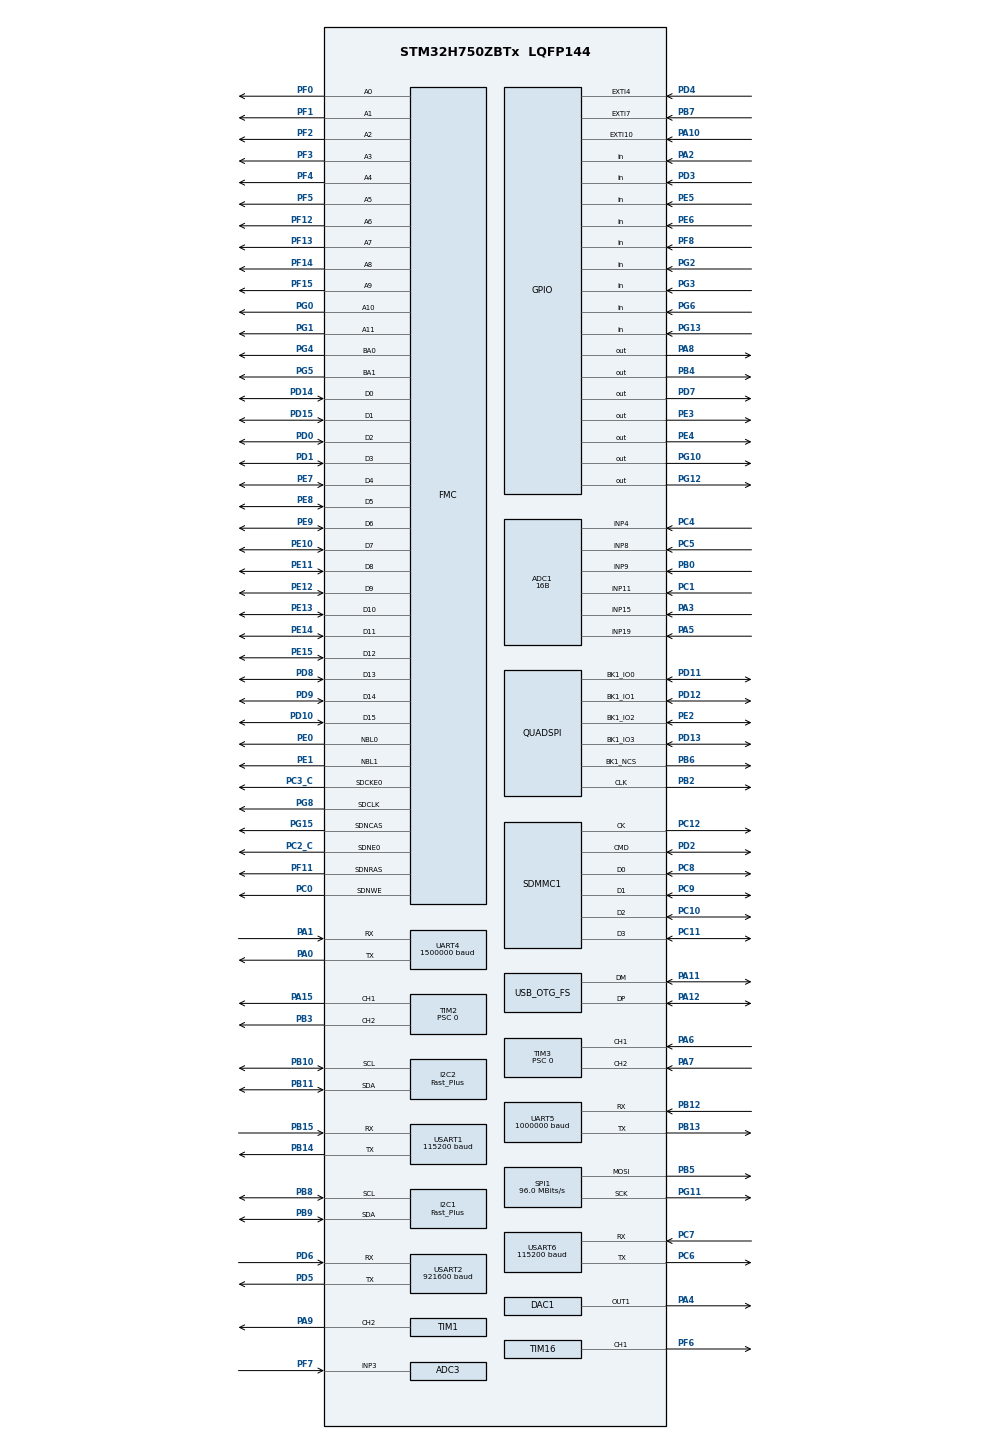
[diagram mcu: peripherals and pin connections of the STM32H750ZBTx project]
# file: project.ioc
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ADC1.Channel-12\#ChannelRegularConversion=ADC_CHANNEL_9
ADC1.Channel-14\#ChannelRegularConversion=ADC_CHANNEL_11
ADC1.Channel-15\#ChannelRegularConversion=ADC_CHANNEL_15
ADC1.Channel-16\#ChannelRegularConversion=ADC_CHANNEL_19
ADC1.Channel-17\#ChannelRegularConversion=ADC_CHANNEL_8
ADC1.Channel-18\#ChannelRegularConversion=ADC_CHANNEL_4
ADC1.ClockPrescaler=ADC_CLOCK_ASYNC_DIV1
ADC1.ClockPrescalerADC3=ADC_CLOCK_ASYNC_DIV1
ADC1.ContinuousConvMode=ENABLE
ADC1.ConversionDataManagement=ADC_CONVERSIONDATA_DMA_CIRCULAR
ADC1.DiscontinuousConvMode=DISABLE
ADC1.EOCSelection=ADC_EOC_SEQ_CONV
ADC1.EnableInjectedConversion=DISABLE
ADC1.EnableRegularConversion=ENABLE
ADC1.NbrOfConversion=6
ADC1.NbrOfConversionFlag=1
ADC1.OffsetNumber-12\#ChannelRegularConversion=ADC_OFFSET_NONE
ADC1.OffsetNumber-14\#ChannelRegularConversion=ADC_OFFSET_NONE
ADC1.OffsetNumber-15\#ChannelRegularConversion=ADC_OFFSET_NONE
ADC1.OffsetNumber-16\#ChannelRegularConversion=ADC_OFFSET_NONE
ADC1.OffsetNumber-17\#ChannelRegularConversion=ADC_OFFSET_NONE
ADC1.OffsetNumber-18\#ChannelRegularConversion=ADC_OFFSET_NONE
ADC1.OffsetSignedSaturation-12\#ChannelRegularConversion=DISABLE
ADC1.OffsetSignedSaturation-14\#ChannelRegularConversion=DISABLE
ADC1.OffsetSignedSaturation-15\#ChannelRegularConversion=DISABLE
ADC1.OffsetSignedSaturation-16\#ChannelRegularConversion=DISABLE
ADC1.OffsetSignedSaturation-17\#ChannelRegularConversion=DISABLE
ADC1.OffsetSignedSaturation-18\#ChannelRegularConversion=DISABLE
ADC1.Overrun=ADC_OVR_DATA_OVERWRITTEN
ADC1.OversamplingMode=DISABLE
ADC1.Rank-12\#ChannelRegularConversion=1
ADC1.Rank-14\#ChannelRegularConversion=2
ADC1.Rank-15\#ChannelRegularConversion=3
ADC1.Rank-16\#ChannelRegularConversion=4
ADC1.Rank-17\#ChannelRegularConversion=5
ADC1.Rank-18\#ChannelRegularConversion=6
ADC1.Resolution=ADC_RESOLUTION_16B
ADC1.SamplingTime-12\#ChannelRegularConversion=ADC_SAMPLETIME_810CYCLES_5
ADC1.SamplingTime-14\#ChannelRegularConversion=ADC_SAMPLETIME_810CYCLES_5
ADC1.SamplingTime-15\#ChannelRegularConversion=ADC_SAMPLETIME_810CYCLES_5
ADC1.SamplingTime-16\#ChannelRegularConversion=ADC_SAMPLETIME_810CYCLES_5
ADC1.SamplingTime-17\#ChannelRegularConversion=ADC_SAMPLETIME_810CYCLES_5
ADC1.SamplingTime-18\#ChannelRegularConversion=ADC_SAMPLETIME_810CYCLES_5
ADC1.master=1
ADC3.Channel-1\#ChannelRegularConversion=ADC_CHANNEL_3
ADC3.ClockPrescaler=ADC_CLOCK_ASYNC_DIV1
ADC3.ClockPrescalerADC3=ADC_CLOCK_ASYNC_DIV1
ADC3.ContinuousConvMode=ENABLE
ADC3.ConversionDataManagement=ADC_CONVERSIONDATA_DMA_CIRCULAR
ADC3.EOCSelection=ADC_EOC_SEQ_CONV
ADC3.NbrOfConversionFlag=1
ADC3.OffsetNumber-1\#ChannelRegularConversion=ADC_OFFSET_NONE
ADC3.OffsetSignedSaturation-1\#ChannelRegularConversion=DISABLE
ADC3.Overrun=ADC_OVR_DATA_OVERWRITTEN
ADC3.Rank-1\#ChannelRegularConversion=1
ADC3.SamplingTime-1\#ChannelRegularConversion=ADC_SAMPLETIME_810CYCLES_5
CORTEX_M7.AccessPermission-Cortex_Memory_Protection_Unit_Region0_Settings=MPU_REGION_FULL_ACCESS
CORTEX_M7.AccessPermission-Cortex_Memory_Protection_Unit_Region1_Settings=MPU_REGION_FULL_ACCESS
CORTEX_M7.AccessPermission-Cortex_Memory_Protection_Unit_Region2_Settings=MPU_REGION_FULL_ACCESS
CORTEX_M7.AccessPermission_Spec=MPU_REGION_FULL_ACCESS
CORTEX_M7.BaseAddress-Cortex_Memory_Protection_Unit_Region0_Settings=0x24000000
CORTEX_M7.BaseAddress-Cortex_Memory_Protection_Unit_Region1_Settings=0x30000000
CORTEX_M7.BaseAddress-Cortex_Memory_Protection_Unit_Region2_Settings=0x30020000
CORTEX_M7.BaseAddress_Spec=0x24000000
CORTEX_M7.CPU_DCache=Enabled
CORTEX_M7.CPU_ICache=Enabled
CORTEX_M7.DisableExec_Spec=MPU_INSTRUCTION_ACCESS_ENABLE
CORTEX_M7.Enable-Cortex_Memory_Protection_Unit_Region0_Settings=MPU_REGION_ENABLE
CORTEX_M7.Enable-Cortex_Memory_Protection_Unit_Region1_Settings=MPU_REGION_ENABLE
CORTEX_M7.Enable-Cortex_Memory_Protection_Unit_Region2_Settings=MPU_REGION_ENABLE
CORTEX_M7.IsBufferable-Cortex_Memory_Protection_Unit_Region0_Settings=MPU_ACCESS_NOT_BUFFERABLE
CORTEX_M7.IsBufferable-Cortex_Memory_Protection_Unit_Region1_Settings=MPU_ACCESS_NOT_BUFFERABLE
CORTEX_M7.IsBufferable-Cortex_Memory_Protection_Unit_Region2_Settings=MPU_ACCESS_NOT_BUFFERABLE
CORTEX_M7.IsBufferable_Spec=MPU_ACCESS_BUFFERABLE
CORTEX_M7.IsCacheable-Cortex_Memory_Protection_Unit_Region0_Settings=MPU_ACCESS_CACHEABLE
CORTEX_M7.IsCacheable-Cortex_Memory_Protection_Unit_Region1_Settings=MPU_ACCESS_CACHEABLE
CORTEX_M7.IsCacheable-Cortex_Memory_Protection_Unit_Region2_Settings=MPU_ACCESS_CACHEABLE
CORTEX_M7.IsCacheable_Spec=MPU_ACCESS_CACHEABLE
CORTEX_M7.IsShareable_Spec=MPU_ACCESS_NOT_SHAREABLE
CORTEX_M7.MPU_Control=MPU_HFNMI_PRIVDEF
CORTEX_M7.Size-Cortex_Memory_Protection_Unit_Region0_Settings=MPU_REGION_SIZE_512KB
CORTEX_M7.Size-Cortex_Memory_Protection_Unit_Region1_Settings=MPU_REGION_SIZE_128KB
CORTEX_M7.Size-Cortex_Memory_Protection_Unit_Region2_Settings=MPU_REGION_SIZE_128KB
CORTEX_M7.Size_Spec=MPU_REGION_SIZE_512KB
CORTEX_M7.SubRegionDisable_Spec=0
CORTEX_M7.TypeExtField-Cortex_Memory_Protection_Unit_Region0_Settings=MPU_TEX_LEVEL0
CORTEX_M7.TypeExtField-Cortex_Memory_Protection_Unit_Region1_Settings=MPU_TEX_LEVEL0
CORTEX_M7.TypeExtField-Cortex_Memory_Protection_Unit_Region2_Settings=MPU_TEX_LEVEL0
CORTEX_M7.TypeExtField_Spec=MPU_TEX_LEVEL1
CORTEX_M7.default_mode_Activation=0
DAC1.DAC1_OutputBuffer-DAC_OUT1=DAC_OUTPUTBUFFER_DISABLE
DAC1.DAC_Channel-DAC_OUT1=DAC_CHANNEL_1
DAC1.DAC_Trigger-DAC_OUT1=DAC_TRIGGER_T15_TRGO
Dma.ADC1.2.Direction=DMA_PERIPH_TO_MEMORY
Dma.ADC1.2.EventEnable=DISABLE
Dma.ADC1.2.FIFOMode=DMA_FIFOMODE_DISABLE
Dma.ADC1.2.Instance=DMA2_Stream0
Dma.ADC1.2.MemDataAlignment=DMA_MDATAALIGN_HALFWORD
Dma.ADC1.2.MemInc=DMA_MINC_ENABLE
Dma.ADC1.2.Mode=DMA_CIRCULAR
Dma.ADC1.2.PeriphDataAlignment=DMA_PDATAALIGN_HALFWORD
Dma.ADC1.2.PeriphInc=DMA_PINC_DISABLE
Dma.ADC1.2.Polarity=HAL_DMAMUX_REQ_GEN_RISING
Dma.ADC1.2.Priority=DMA_PRIORITY_HIGH
Dma.ADC1.2.RequestNumber=1
Dma.ADC1.2.SignalID=NONE
Dma.ADC1.2.SyncEnable=DISABLE
Dma.ADC1.2.SyncPolarity=HAL_DMAMUX_SYNC_NO_EVENT
Dma.ADC1.2.SyncRequestNumber=1
Dma.ADC1.2.SyncSignalID=NONE
Dma.ADC3.9.Direction=DMA_PERIPH_TO_MEMORY
Dma.ADC3.9.EventEnable=DISABLE
Dma.ADC3.9.FIFOMode=DMA_FIFOMODE_DISABLE
Dma.ADC3.9.Instance=DMA2_Stream6
Dma.ADC3.9.MemDataAlignment=DMA_MDATAALIGN_HALFWORD
Dma.ADC3.9.MemInc=DMA_MINC_ENABLE
Dma.ADC3.9.Mode=DMA_CIRCULAR
Dma.ADC3.9.PeriphDataAlignment=DMA_PDATAALIGN_HALFWORD
Dma.ADC3.9.PeriphInc=DMA_PINC_DISABLE
Dma.ADC3.9.Polarity=HAL_DMAMUX_REQ_GEN_RISING
Dma.ADC3.9.Priority=DMA_PRIORITY_HIGH
Dma.ADC3.9.RequestNumber=1
Dma.ADC3.9.SignalID=NONE
Dma.ADC3.9.SyncEnable=DISABLE
Dma.ADC3.9.SyncPolarity=HAL_DMAMUX_SYNC_NO_EVENT
Dma.ADC3.9.SyncRequestNumber=1
Dma.ADC3.9.SyncSignalID=NONE
Dma.DAC1_CH1.3.Direction=DMA_MEMORY_TO_PERIPH
Dma.DAC1_CH1.3.EventEnable=DISABLE
Dma.DAC1_CH1.3.FIFOMode=DMA_FIFOMODE_DISABLE
Dma.DAC1_CH1.3.Instance=DMA1_Stream1
Dma.DAC1_CH1.3.MemDataAlignment=DMA_MDATAALIGN_HALFWORD
Dma.DAC1_CH1.3.MemInc=DMA_MINC_ENABLE
Dma.DAC1_CH1.3.Mode=DMA_NORMAL
Dma.DAC1_CH1.3.PeriphDataAlignment=DMA_PDATAALIGN_HALFWORD
Dma.DAC1_CH1.3.PeriphInc=DMA_PINC_DISABLE
Dma.DAC1_CH1.3.Polarity=HAL_DMAMUX_REQ_GEN_RISING
Dma.DAC1_CH1.3.Priority=DMA_PRIORITY_LOW
Dma.DAC1_CH1.3.RequestNumber=1
Dma.DAC1_CH1.3.SignalID=NONE
Dma.DAC1_CH1.3.SyncEnable=DISABLE
Dma.DAC1_CH1.3.SyncPolarity=HAL_DMAMUX_SYNC_NO_EVENT
Dma.DAC1_CH1.3.SyncRequestNumber=1
Dma.DAC1_CH1.3.SyncSignalID=NONE
Dma.Request0=UART4_TX
Dma.Request1=TIM16_CH1
Dma.Request10=USART6_RX
Dma.Request11=USART1_RX
Dma.Request12=USART1_TX
Dma.Request13=UART4_RX
Dma.Request14=USART6_TX
Dma.Request2=ADC1
Dma.Request3=DAC1_CH1
Dma.Request4=TIM1_CH2
Dma.Request5=SPI1_TX
Dma.Request6=USART2_RX
Dma.Request7=USART2_TX
Dma.Request8=UART5_TX
Dma.Request9=ADC3
Dma.SPI1_TX.5.Direction=DMA_MEMORY_TO_PERIPH
Dma.SPI1_TX.5.EventEnable=DISABLE
Dma.SPI1_TX.5.FIFOMode=DMA_FIFOMODE_DISABLE
Dma.SPI1_TX.5.Instance=DMA1_Stream6
Dma.SPI1_TX.5.MemDataAlignment=DMA_MDATAALIGN_BYTE
Dma.SPI1_TX.5.MemInc=DMA_MINC_ENABLE
Dma.SPI1_TX.5.Mode=DMA_NORMAL
Dma.SPI1_TX.5.PeriphDataAlignment=DMA_PDATAALIGN_BYTE
Dma.SPI1_TX.5.PeriphInc=DMA_PINC_DISABLE
Dma.SPI1_TX.5.Polarity=HAL_DMAMUX_REQ_GEN_RISING
Dma.SPI1_TX.5.Priority=DMA_PRIORITY_LOW
Dma.SPI1_TX.5.RequestNumber=1
Dma.SPI1_TX.5.SignalID=NONE
Dma.SPI1_TX.5.SyncEnable=DISABLE
Dma.SPI1_TX.5.SyncPolarity=HAL_DMAMUX_SYNC_NO_EVENT
Dma.SPI1_TX.5.SyncRequestNumber=1
Dma.SPI1_TX.5.SyncSignalID=NONE
Dma.TIM16_CH1.1.Direction=DMA_MEMORY_TO_PERIPH
Dma.TIM16_CH1.1.EventEnable=DISABLE
Dma.TIM16_CH1.1.FIFOMode=DMA_FIFOMODE_DISABLE
Dma.TIM16_CH1.1.Instance=DMA1_Stream0
Dma.TIM16_CH1.1.MemDataAlignment=DMA_MDATAALIGN_HALFWORD
Dma.TIM16_CH1.1.MemInc=DMA_MINC_ENABLE
Dma.TIM16_CH1.1.Mode=DMA_CIRCULAR
Dma.TIM16_CH1.1.PeriphDataAlignment=DMA_PDATAALIGN_HALFWORD
Dma.TIM16_CH1.1.PeriphInc=DMA_PINC_DISABLE
Dma.TIM16_CH1.1.Polarity=HAL_DMAMUX_REQ_GEN_RISING
Dma.TIM16_CH1.1.Priority=DMA_PRIORITY_LOW
Dma.TIM16_CH1.1.RequestNumber=1
Dma.TIM16_CH1.1.SignalID=NONE
Dma.TIM16_CH1.1.SyncEnable=DISABLE
Dma.TIM16_CH1.1.SyncPolarity=HAL_DMAMUX_SYNC_NO_EVENT
Dma.TIM16_CH1.1.SyncRequestNumber=1
Dma.TIM16_CH1.1.SyncSignalID=NONE
Dma.TIM1_CH2.4.Direction=DMA_MEMORY_TO_PERIPH
Dma.TIM1_CH2.4.EventEnable=DISABLE
Dma.TIM1_CH2.4.FIFOMode=DMA_FIFOMODE_DISABLE
Dma.TIM1_CH2.4.Instance=DMA1_Stream3
Dma.TIM1_CH2.4.MemDataAlignment=DMA_MDATAALIGN_HALFWORD
Dma.TIM1_CH2.4.MemInc=DMA_MINC_ENABLE
Dma.TIM1_CH2.4.Mode=DMA_NORMAL
Dma.TIM1_CH2.4.PeriphDataAlignment=DMA_PDATAALIGN_HALFWORD
Dma.TIM1_CH2.4.PeriphInc=DMA_PINC_DISABLE
Dma.TIM1_CH2.4.Polarity=HAL_DMAMUX_REQ_GEN_RISING
Dma.TIM1_CH2.4.Priority=DMA_PRIORITY_LOW
Dma.TIM1_CH2.4.RequestNumber=1
Dma.TIM1_CH2.4.SignalID=NONE
Dma.TIM1_CH2.4.SyncEnable=DISABLE
Dma.TIM1_CH2.4.SyncPolarity=HAL_DMAMUX_SYNC_NO_EVENT
Dma.TIM1_CH2.4.SyncRequestNumber=1
Dma.TIM1_CH2.4.SyncSignalID=NONE
Dma.UART4_RX.13.Direction=DMA_PERIPH_TO_MEMORY
Dma.UART4_RX.13.EventEnable=DISABLE
Dma.UART4_RX.13.FIFOMode=DMA_FIFOMODE_DISABLE
Dma.UART4_RX.13.Instance=DMA2_Stream5
Dma.UART4_RX.13.MemDataAlignment=DMA_MDATAALIGN_BYTE
Dma.UART4_RX.13.MemInc=DMA_MINC_ENABLE
Dma.UART4_RX.13.Mode=DMA_CIRCULAR
Dma.UART4_RX.13.PeriphDataAlignment=DMA_PDATAALIGN_BYTE
Dma.UART4_RX.13.PeriphInc=DMA_PINC_DISABLE
Dma.UART4_RX.13.Polarity=HAL_DMAMUX_REQ_GEN_RISING
Dma.UART4_RX.13.Priority=DMA_PRIORITY_LOW
Dma.UART4_RX.13.RequestNumber=1
Dma.UART4_RX.13.SignalID=NONE
Dma.UART4_RX.13.SyncEnable=DISABLE
Dma.UART4_RX.13.SyncPolarity=HAL_DMAMUX_SYNC_NO_EVENT
Dma.UART4_RX.13.SyncRequestNumber=1
Dma.UART4_RX.13.SyncSignalID=NONE
Dma.UART4_TX.0.Direction=DMA_MEMORY_TO_PERIPH
Dma.UART4_TX.0.EventEnable=DISABLE
Dma.UART4_TX.0.FIFOMode=DMA_FIFOMODE_DISABLE
Dma.UART4_TX.0.Instance=DMA1_Stream2
Dma.UART4_TX.0.MemDataAlignment=DMA_MDATAALIGN_BYTE
Dma.UART4_TX.0.MemInc=DMA_MINC_ENABLE
Dma.UART4_TX.0.Mode=DMA_NORMAL
Dma.UART4_TX.0.PeriphDataAlignment=DMA_PDATAALIGN_BYTE
Dma.UART4_TX.0.PeriphInc=DMA_PINC_DISABLE
Dma.UART4_TX.0.Polarity=HAL_DMAMUX_REQ_GEN_RISING
Dma.UART4_TX.0.Priority=DMA_PRIORITY_LOW
Dma.UART4_TX.0.RequestNumber=1
Dma.UART4_TX.0.SignalID=NONE
Dma.UART4_TX.0.SyncEnable=DISABLE
Dma.UART4_TX.0.SyncPolarity=HAL_DMAMUX_SYNC_NO_EVENT
Dma.UART4_TX.0.SyncRequestNumber=1
Dma.UART4_TX.0.SyncSignalID=NONE
Dma.UART5_TX.8.Direction=DMA_MEMORY_TO_PERIPH
Dma.UART5_TX.8.EventEnable=DISABLE
Dma.UART5_TX.8.FIFOMode=DMA_FIFOMODE_DISABLE
Dma.UART5_TX.8.Instance=DMA2_Stream1
Dma.UART5_TX.8.MemDataAlignment=DMA_MDATAALIGN_BYTE
Dma.UART5_TX.8.MemInc=DMA_MINC_ENABLE
Dma.UART5_TX.8.Mode=DMA_NORMAL
Dma.UART5_TX.8.PeriphDataAlignment=DMA_PDATAALIGN_BYTE
Dma.UART5_TX.8.PeriphInc=DMA_PINC_DISABLE
Dma.UART5_TX.8.Polarity=HAL_DMAMUX_REQ_GEN_RISING
Dma.UART5_TX.8.Priority=DMA_PRIORITY_LOW
Dma.UART5_TX.8.RequestNumber=1
Dma.UART5_TX.8.SignalID=NONE
Dma.UART5_TX.8.SyncEnable=DISABLE
Dma.UART5_TX.8.SyncPolarity=HAL_DMAMUX_SYNC_NO_EVENT
Dma.UART5_TX.8.SyncRequestNumber=1
Dma.UART5_TX.8.SyncSignalID=NONE
Dma.USART1_RX.11.Direction=DMA_PERIPH_TO_MEMORY
Dma.USART1_RX.11.EventEnable=DISABLE
Dma.USART1_RX.11.FIFOMode=DMA_FIFOMODE_DISABLE
Dma.USART1_RX.11.Instance=DMA2_Stream7
Dma.USART1_RX.11.MemDataAlignment=DMA_MDATAALIGN_BYTE
Dma.USART1_RX.11.MemInc=DMA_MINC_ENABLE
Dma.USART1_RX.11.Mode=DMA_CIRCULAR
Dma.USART1_RX.11.PeriphDataAlignment=DMA_PDATAALIGN_BYTE
Dma.USART1_RX.11.PeriphInc=DMA_PINC_DISABLE
Dma.USART1_RX.11.Polarity=HAL_DMAMUX_REQ_GEN_RISING
Dma.USART1_RX.11.Priority=DMA_PRIORITY_LOW
Dma.USART1_RX.11.RequestNumber=1
Dma.USART1_RX.11.SignalID=NONE
Dma.USART1_RX.11.SyncEnable=DISABLE
Dma.USART1_RX.11.SyncPolarity=HAL_DMAMUX_SYNC_NO_EVENT
Dma.USART1_RX.11.SyncRequestNumber=1
Dma.USART1_RX.11.SyncSignalID=NONE
Dma.USART1_TX.12.Direction=DMA_MEMORY_TO_PERIPH
Dma.USART1_TX.12.EventEnable=DISABLE
Dma.USART1_TX.12.FIFOMode=DMA_FIFOMODE_DISABLE
Dma.USART1_TX.12.Instance=DMA1_Stream4
Dma.USART1_TX.12.MemDataAlignment=DMA_MDATAALIGN_BYTE
Dma.USART1_TX.12.MemInc=DMA_MINC_ENABLE
Dma.USART1_TX.12.Mode=DMA_NORMAL
Dma.USART1_TX.12.PeriphDataAlignment=DMA_PDATAALIGN_BYTE
Dma.USART1_TX.12.PeriphInc=DMA_PINC_DISABLE
Dma.USART1_TX.12.Polarity=HAL_DMAMUX_REQ_GEN_RISING
Dma.USART1_TX.12.Priority=DMA_PRIORITY_LOW
Dma.USART1_TX.12.RequestNumber=1
Dma.USART1_TX.12.SignalID=NONE
Dma.USART1_TX.12.SyncEnable=DISABLE
Dma.USART1_TX.12.SyncPolarity=HAL_DMAMUX_SYNC_NO_EVENT
Dma.USART1_TX.12.SyncRequestNumber=1
Dma.USART1_TX.12.SyncSignalID=NONE
Dma.USART2_RX.6.Direction=DMA_PERIPH_TO_MEMORY
Dma.USART2_RX.6.EventEnable=DISABLE
Dma.USART2_RX.6.FIFOMode=DMA_FIFOMODE_DISABLE
Dma.USART2_RX.6.Instance=DMA1_Stream5
Dma.USART2_RX.6.MemDataAlignment=DMA_MDATAALIGN_BYTE
Dma.USART2_RX.6.MemInc=DMA_MINC_ENABLE
Dma.USART2_RX.6.Mode=DMA_CIRCULAR
Dma.USART2_RX.6.PeriphDataAlignment=DMA_PDATAALIGN_BYTE
Dma.USART2_RX.6.PeriphInc=DMA_PINC_DISABLE
Dma.USART2_RX.6.Polarity=HAL_DMAMUX_REQ_GEN_RISING
Dma.USART2_RX.6.Priority=DMA_PRIORITY_LOW
Dma.USART2_RX.6.RequestNumber=1
Dma.USART2_RX.6.SignalID=NONE
Dma.USART2_RX.6.SyncEnable=DISABLE
Dma.USART2_RX.6.SyncPolarity=HAL_DMAMUX_SYNC_NO_EVENT
Dma.USART2_RX.6.SyncRequestNumber=1
Dma.USART2_RX.6.SyncSignalID=NONE
Dma.USART2_TX.7.Direction=DMA_MEMORY_TO_PERIPH
Dma.USART2_TX.7.EventEnable=DISABLE
Dma.USART2_TX.7.FIFOMode=DMA_FIFOMODE_DISABLE
Dma.USART2_TX.7.Instance=DMA1_Stream7
Dma.USART2_TX.7.MemDataAlignment=DMA_MDATAALIGN_BYTE
Dma.USART2_TX.7.MemInc=DMA_MINC_ENABLE
Dma.USART2_TX.7.Mode=DMA_NORMAL
Dma.USART2_TX.7.PeriphDataAlignment=DMA_PDATAALIGN_BYTE
Dma.USART2_TX.7.PeriphInc=DMA_PINC_DISABLE
Dma.USART2_TX.7.Polarity=HAL_DMAMUX_REQ_GEN_RISING
Dma.USART2_TX.7.Priority=DMA_PRIORITY_LOW
Dma.USART2_TX.7.RequestNumber=1
Dma.USART2_TX.7.SignalID=NONE
Dma.USART2_TX.7.SyncEnable=DISABLE
Dma.USART2_TX.7.SyncPolarity=HAL_DMAMUX_SYNC_NO_EVENT
Dma.USART2_TX.7.SyncRequestNumber=1
Dma.USART2_TX.7.SyncSignalID=NONE
Dma.USART6_RX.10.Direction=DMA_PERIPH_TO_MEMORY
Dma.USART6_RX.10.EventEnable=DISABLE
Dma.USART6_RX.10.FIFOMode=DMA_FIFOMODE_DISABLE
Dma.USART6_RX.10.Instance=DMA2_Stream4
Dma.USART6_RX.10.MemDataAlignment=DMA_MDATAALIGN_BYTE
Dma.USART6_RX.10.MemInc=DMA_MINC_ENABLE
Dma.USART6_RX.10.Mode=DMA_CIRCULAR
Dma.USART6_RX.10.PeriphDataAlignment=DMA_PDATAALIGN_BYTE
Dma.USART6_RX.10.PeriphInc=DMA_PINC_DISABLE
Dma.USART6_RX.10.Polarity=HAL_DMAMUX_REQ_GEN_RISING
Dma.USART6_RX.10.Priority=DMA_PRIORITY_LOW
Dma.USART6_RX.10.RequestNumber=1
Dma.USART6_RX.10.SignalID=NONE
Dma.USART6_RX.10.SyncEnable=DISABLE
Dma.USART6_RX.10.SyncPolarity=HAL_DMAMUX_SYNC_NO_EVENT
Dma.USART6_RX.10.SyncRequestNumber=1
Dma.USART6_RX.10.SyncSignalID=NONE
Dma.USART6_TX.14.Direction=DMA_MEMORY_TO_PERIPH
Dma.USART6_TX.14.EventEnable=DISABLE
Dma.USART6_TX.14.FIFOMode=DMA_FIFOMODE_DISABLE
Dma.USART6_TX.14.Instance=DMA2_Stream2
Dma.USART6_TX.14.MemDataAlignment=DMA_MDATAALIGN_BYTE
Dma.USART6_TX.14.MemInc=DMA_MINC_ENABLE
Dma.USART6_TX.14.Mode=DMA_NORMAL
Dma.USART6_TX.14.PeriphDataAlignment=DMA_PDATAALIGN_BYTE
Dma.USART6_TX.14.PeriphInc=DMA_PINC_DISABLE
Dma.USART6_TX.14.Polarity=HAL_DMAMUX_REQ_GEN_RISING
Dma.USART6_TX.14.Priority=DMA_PRIORITY_LOW
Dma.USART6_TX.14.RequestNumber=1
Dma.USART6_TX.14.SignalID=NONE
Dma.USART6_TX.14.SyncEnable=DISABLE
Dma.USART6_TX.14.SyncPolarity=HAL_DMAMUX_SYNC_NO_EVENT
Dma.USART6_TX.14.SyncRequestNumber=1
Dma.USART6_TX.14.SyncSignalID=NONE
FATFS.BSP.number=1
FATFS._CODE_PAGE=936
FATFS._FS_EXFAT=1
FATFS._FS_TIMEOUT=1000
FATFS._USE_LFN=3
FATFS._USE_MUTEX=1
FATFS._USE_TRIM=1
FATFS0.BSP.STBoard=false
FATFS0.BSP.api=Unknown
FATFS0.BSP.instance=PG6
FATFS0.BSP.ip=GPIO
FATFS0.BSP.mode=Input
FATFS0.BSP.name=Detect_SDIO
FATFS0.BSP.solution=PG6
FMC.CASLatency1=FMC_SDRAM_CAS_LATENCY_3
FMC.ExitSelfRefreshDelay1=7
FMC.LoadToActiveDelay1=2
FMC.RCDDelay1=2
FMC.RPDelay1=2
FMC.ReadBurst1=FMC_SDRAM_RBURST_ENABLE
FMC.RowCycleDelay1=7
FMC.SDClockPeriod1=FMC_SDRAM_CLOCK_PERIOD_2
FMC.SelfRefreshTime1=4
FMC.WriteRecoveryTime1=3
FREERTOS.HEAP_NUMBER=5
FREERTOS.INCLUDE_pcTaskGetTaskName=1
FREERTOS.INCLUDE_xSemaphoreGetMutexHolder=1
FREERTOS.INCLUDE_xTaskGetHandle=1
FREERTOS.Tasks01=defaultTask,8,1024,StartDefaultTask,Default,NULL,Static,defaultTaskBuffer,defaultTaskControlBlock
FREERTOS.configCHECK_FOR_STACK_OVERFLOW=1
FREERTOS.configENABLE_BACKWARD_COMPATIBILITY=1
FREERTOS.configENABLE_FPU=1
FREERTOS.configGENERATE_RUN_TIME_STATS=1
FREERTOS.configLIBRARY_MAX_SYSCALL_INTERRUPT_PRIORITY=11
FREERTOS.configMAX_TASK_NAME_LEN=64
FREERTOS.configMINIMAL_STACK_SIZE=256
FREERTOS.configRECORD_STACK_HIGH_ADDRESS=1
FREERTOS.configTOTAL_HEAP_SIZE=1024*640
FREERTOS.configUSE_CO_ROUTINES=1
FREERTOS.configUSE_DAEMON_TASK_STARTUP_HOOK=0
FREERTOS.configUSE_IDLE_HOOK=0
FREERTOS.configUSE_MALLOC_FAILED_HOOK=1
FREERTOS.configUSE_STATS_FORMATTING_FUNCTIONS=1
FREERTOS.configUSE_TICK_HOOK=0
I2C1.CustomTiming=Disabled
I2C1.I2C_Fall_Time=0
I2C1.I2C_Rise_Time=0
I2C1.I2C_Speed_Mode=I2C_Fast_Plus
I2C1.Timing=0x0050174F
I2C2.CustomTiming=Disabled
I2C2.I2C_Speed_Mode=I2C_Fast_Plus
I2C2.Timing=0x0050174F
IWDG1.Prescaler=IWDG_PRESCALER_32
IWDG1.Reload=4000
IWDG1.Window=4000
Mcu.Family=STM32H7
Mcu.Name=STM32H750ZBTx
Mcu.Package=LQFP144
NVIC.DMA1_Stream0_IRQn=true\:11\:0\:false\:false\:true\:false\:false\:true\:true
NVIC.DMA1_Stream1_IRQn=true\:11\:0\:false\:false\:true\:false\:false\:true\:true
NVIC.DMA1_Stream2_IRQn=true\:11\:0\:true\:false\:true\:false\:false\:true\:true
NVIC.DMA1_Stream3_IRQn=true\:11\:0\:true\:false\:true\:false\:false\:true\:true
NVIC.DMA1_Stream4_IRQn=true\:11\:0\:true\:false\:true\:false\:false\:true\:true
NVIC.DMA1_Stream5_IRQn=true\:11\:0\:true\:false\:true\:false\:false\:true\:true
NVIC.DMA1_Stream6_IRQn=true\:8\:0\:true\:false\:true\:false\:false\:true\:true
NVIC.DMA1_Stream7_IRQn=true\:11\:0\:true\:false\:true\:false\:false\:true\:true
NVIC.DMA2_Stream0_IRQn=true\:11\:0\:false\:false\:true\:false\:false\:true\:true
NVIC.DMA2_Stream1_IRQn=true\:11\:0\:true\:false\:true\:false\:false\:true\:true
NVIC.DMA2_Stream2_IRQn=true\:11\:0\:true\:false\:true\:false\:false\:true\:true
NVIC.DMA2_Stream4_IRQn=true\:11\:0\:true\:false\:true\:false\:false\:true\:true
NVIC.DMA2_Stream5_IRQn=true\:11\:0\:true\:false\:true\:false\:false\:true\:true
NVIC.DMA2_Stream6_IRQn=true\:11\:0\:false\:false\:true\:false\:false\:true\:true
NVIC.DMA2_Stream7_IRQn=true\:11\:0\:true\:false\:true\:false\:false\:true\:true
NVIC.EXTI15_10_IRQn=true\:8\:0\:true\:false\:true\:false\:true\:true\:true
NVIC.EXTI4_IRQn=true\:9\:0\:true\:false\:true\:false\:true\:true\:true
NVIC.EXTI9_5_IRQn=true\:15\:0\:true\:false\:true\:false\:true\:true\:true
NVIC.I2C1_ER_IRQn=true\:4\:0\:true\:false\:true\:false\:true\:true\:true
NVIC.I2C2_ER_IRQn=true\:4\:0\:true\:false\:true\:false\:true\:true\:true
NVIC.OTG_FS_IRQn=true\:11\:0\:true\:false\:true\:false\:false\:true\:true
NVIC.PriorityGroup=NVIC_PRIORITYGROUP_4
NVIC.SDMMC1_IRQn=true\:11\:0\:true\:false\:true\:false\:true\:true\:true
NVIC.SPI1_IRQn=true\:11\:0\:true\:false\:true\:false\:false\:true\:true
NVIC.TIM5_IRQn=true\:3\:0\:true\:false\:true\:false\:true\:true\:true
NVIC.TIM8_BRK_TIM12_IRQn=true\:15\:0\:true\:false\:true\:false\:false\:true\:true
NVIC.TimeBase=TIM8_BRK_TIM12_IRQn
NVIC.TimeBaseIP=TIM12
NVIC.UART4_IRQn=true\:11\:0\:true\:false\:true\:false\:true\:true\:true
NVIC.USART1_IRQn=true\:10\:0\:true\:false\:true\:false\:true\:true\:true
NVIC.USART2_IRQn=true\:10\:0\:true\:false\:true\:false\:true\:true\:true
NVIC.USART6_IRQn=true\:10\:0\:true\:false\:true\:false\:true\:true\:true
PA0.GPIO_ModeDefaultPP=GPIO_MODE_AF_PP
PA0.GPIO_PuPd=GPIO_PULLUP
PA0.GPIO_Speed=GPIO_SPEED_FREQ_HIGH
PA0.Mode=Asynchronous
PA0.Signal=UART4_TX
PA1.GPIO_ModeDefaultPP=GPIO_MODE_AF_PP
PA1.GPIO_PuPd=GPIO_PULLUP
PA1.GPIO_Speed=GPIO_SPEED_FREQ_HIGH
PA1.Mode=Asynchronous
PA1.Signal=UART4_RX
PA10.GPIO_ModeDefaultEXTI=GPIO_MODE_IT_RISING
PA10.GPIO_PuPd=GPIO_PULLDOWN
PA10.Signal=GPXTI10
PA11.GPIO_Speed=GPIO_SPEED_FREQ_VERY_HIGH
PA11.Mode=Device_Only
PA11.Signal=USB_OTG_FS_DM
PA12.GPIO_PuPd=GPIO_PULLUP
PA12.GPIO_Speed=GPIO_SPEED_FREQ_VERY_HIGH
PA12.Mode=Device_Only
PA12.Signal=USB_OTG_FS_DP
PA13\ (JTMS/SWDIO).Mode=Serial_Wire
PA13\ (JTMS/SWDIO).Signal=DEBUG_JTMS-SWDIO
PA14\ (JTCK/SWCLK).Mode=Serial_Wire
PA14\ (JTCK/SWCLK).Signal=DEBUG_JTCK-SWCLK
PA15\ (JTDI).GPIO_PuPd=GPIO_PULLDOWN
PA15\ (JTDI).GPIO_Speed=GPIO_SPEED_FREQ_MEDIUM
PA15\ (JTDI).Signal=S_TIM2_CH1_ETR
PA2.GPIO_PuPd=GPIO_PULLUP
PA2.Signal=GPIO_Input
PA3.Signal=ADCx_INP15
PA4.Signal=COMP_DAC11_group
PA5.Signal=ADCx_INP19
PA6.GPIO_PuPd=GPIO_PULLUP
PA6.Signal=S_TIM3_CH1
PA7.GPIO_PuPd=GPIO_PULLUP
PA7.Signal=S_TIM3_CH2
PA8.GPIO_PuPd=GPIO_NOPULL
PA8.GPIO_Speed=GPIO_SPEED_FREQ_MEDIUM
PA8.Signal=GPIO_Output
PA9.GPIO_PuPd=GPIO_PULLDOWN
PA9.GPIO_Speed=GPIO_SPEED_FREQ_LOW
PA9.Signal=S_TIM1_CH2
PB0.Signal=ADCx_INP9
PB10.Mode=I2C
PB10.Signal=I2C2_SCL
PB11.GPIO_Pu=GPIO_PULLUP
PB11.Mode=I2C
PB11.Signal=I2C2_SDA
PB12.GPIO_PuPd=GPIO_PULLUP
PB12.GPIO_Speed=GPIO_SPEED_FREQ_MEDIUM
PB12.Mode=Asynchronous
PB12.Signal=UART5_RX
PB13.GPIO_PuPd=GPIO_PULLUP
PB13.GPIO_Speed=GPIO_SPEED_FREQ_MEDIUM
PB13.Mode=Asynchronous
PB13.Signal=UART5_TX
PB14.GPIO_ModeDefaultPP=GPIO_MODE_AF_OD
PB14.GPIO_PuPd=GPIO_NOPULL
PB14.GPIO_Speed=GPIO_SPEED_FREQ_MEDIUM
PB14.Mode=Asynchronous
PB14.Signal=USART1_TX
PB15.GPIO_ModeDefaultPP=GPIO_MODE_AF_OD
PB15.GPIO_PuPd=GPIO_NOPULL
PB15.GPIO_Speed=GPIO_SPEED_FREQ_MEDIUM
PB15.Mode=Asynchronous
PB15.Signal=USART1_RX
PB2.GPIO_Mode=GPIO_MODE_AF_PP
PB2.GPIO_PuPd=GPIO_NOPULL
PB2.GPIO_Speed=GPIO_SPEED_FREQ_VERY_HIGH
PB2.Mode=Single Bank 1
PB2.Signal=QUADSPI_CLK
PB3\ (JTDO/TRACESWO).GPIO_PuPd=GPIO_NOPULL
PB3\ (JTDO/TRACESWO).GPIO_Speed=GPIO_SPEED_FREQ_LOW
PB3\ (JTDO/TRACESWO).PinAttribute=Free
PB3\ (JTDO/TRACESWO).Signal=S_TIM2_CH2
PB4\ (NJTRST).PinAttribute=Free
PB4\ (NJTRST).Signal=GPIO_Output
PB5.GPIO_Speed=GPIO_SPEED_FREQ_VERY_HIGH
PB5.Mode=TX_Only_Simplex_Unidirect_Master
PB5.PinAttribute=Free
PB5.Signal=SPI1_MOSI
PB6.GPIO_Mode=GPIO_MODE_AF_PP
PB6.GPIO_PuPd=GPIO_NOPULL
PB6.GPIO_Speed=GPIO_SPEED_FREQ_VERY_HIGH
PB6.Mode=Single Bank 1
PB6.PinAttribute=Free
PB6.Signal=QUADSPI_BK1_NCS
PB7.GPIO_ModeDefaultEXTI=GPIO_MODE_IT_FALLING
PB7.GPIO_PuPd=GPIO_PULLUP
PB7.PinAttribute=Free
PB7.Signal=GPXTI7
PB8.GPIO_Pu=GPIO_NOPULL
PB8.Mode=I2C
PB8.PinAttribute=Free
PB8.Signal=I2C1_SCL
PB9.GPIO_Pu=GPIO_PULLUP
PB9.Mode=I2C
PB9.PinAttribute=Free
PB9.Signal=I2C1_SDA
PC0.Signal=FMC_SDNWE
PC1.Signal=ADCx_INP11
PC10.GPIO_PuPd=GPIO_PULLUP
PC10.Mode=SD_4_bits_Wide_bus
PC10.Signal=SDMMC1_D2
PC11.GPIO_PuPd=GPIO_PULLUP
PC11.Mode=SD_4_bits_Wide_bus
PC11.Signal=SDMMC1_D3
PC12.GPIO_PuPd=GPIO_PULLUP
PC12.Mode=SD_4_bits_Wide_bus
PC12.Signal=SDMMC1_CK
PC14-OSC32_IN\ (OSC32_IN).Mode=LSE-External-Oscillator
PC14-OSC32_IN\ (OSC32_IN).Signal=RCC_OSC32_IN
PC15-OSC32_OUT\ (OSC32_OUT).Mode=LSE-External-Oscillator
PC15-OSC32_OUT\ (OSC32_OUT).Signal=RCC_OSC32_OUT
PC2_C.Mode=SdramChipSelect1_1
PC2_C.Signal=FMC_SDNE0
PC3_C.Mode=SdramChipSelect1_1
PC3_C.Signal=FMC_SDCKE0
PC4.Signal=ADCx_INP4
PC5.Signal=ADCx_INP8
PC6.GPIO_PuPd=GPIO_PULLUP
PC6.GPIO_Speed=GPIO_SPEED_FREQ_MEDIUM
PC6.Mode=Asynchronous
PC6.Signal=USART6_TX
PC7.GPIO_PuPd=GPIO_PULLUP
PC7.GPIO_Speed=GPIO_SPEED_FREQ_MEDIUM
PC7.Mode=Asynchronous
PC7.Signal=USART6_RX
PC8.GPIO_PuPd=GPIO_PULLUP
PC8.Mode=SD_4_bits_Wide_bus
PC8.Signal=SDMMC1_D0
PC9.GPIO_PuPd=GPIO_PULLUP
PC9.Mode=SD_4_bits_Wide_bus
PC9.Signal=SDMMC1_D1
PD0.Signal=FMC_D2_DA2
PD1.Signal=FMC_D3_DA3
PD10.Signal=FMC_D15_DA15
PD11.GPIO_Mode=GPIO_MODE_AF_PP
PD11.GPIO_PuPd=GPIO_NOPULL
PD11.GPIO_Speed=GPIO_SPEED_FREQ_VERY_HIGH
PD11.Mode=Single Bank 1
PD11.Signal=QUADSPI_BK1_IO0
PD12.GPIO_Mode=GPIO_MODE_AF_PP
PD12.GPIO_PuPd=GPIO_NOPULL
PD12.GPIO_Speed=GPIO_SPEED_FREQ_VERY_HIGH
PD12.Mode=Single Bank 1
PD12.Signal=QUADSPI_BK1_IO1
PD13.GPIO_Mode=GPIO_MODE_AF_PP
PD13.GPIO_PuPd=GPIO_NOPULL
PD13.GPIO_Speed=GPIO_SPEED_FREQ_VERY_HIGH
PD13.Mode=Single Bank 1
PD13.Signal=QUADSPI_BK1_IO3
PD14.Signal=FMC_D0_DA0
PD15.Signal=FMC_D1_DA1
PD2.GPIO_PuPd=GPIO_PULLUP
PD2.Mode=SD_4_bits_Wide_bus
PD2.Signal=SDMMC1_CMD
PD3.GPIO_PuPd=GPIO_PULLUP
PD3.PinAttribute=Free
PD3.Signal=GPIO_Input
PD4.GPIO_ModeDefaultEXTI=GPIO_MODE_IT_RISING
PD4.GPIO_PuPd=GPIO_PULLUP
PD4.PinAttribute=Free
PD4.Signal=GPXTI4
PD5.GPIO_PuPd=GPIO_PULLUP
PD5.GPIO_Speed=GPIO_SPEED_FREQ_MEDIUM
PD5.Mode=Asynchronous
PD5.PinAttribute=Free
PD5.Signal=USART2_TX
PD6.GPIO_PuPd=GPIO_PULLUP
PD6.GPIO_Speed=GPIO_SPEED_FREQ_MEDIUM
PD6.Mode=Asynchronous
PD6.PinAttribute=Free
PD6.Signal=USART2_RX
PD7.PinAttribute=Free
PD7.Signal=GPIO_Output
PD8.Signal=FMC_D13_DA13
PD9.Signal=FMC_D14_DA14
PE0.PinAttribute=Free
PE0.Signal=FMC_NBL0
PE1.PinAttribute=Free
PE1.Signal=FMC_NBL1
PE10.Signal=FMC_D7_DA7
PE11.Signal=FMC_D8_DA8
PE12.Signal=FMC_D9_DA9
PE13.Signal=FMC_D10_DA10
PE14.Signal=FMC_D11_DA11
PE15.Signal=FMC_D12_DA12
PE2.GPIO_Mode=GPIO_MODE_AF_PP
PE2.GPIO_PuPd=GPIO_NOPULL
PE2.GPIO_Speed=GPIO_SPEED_FREQ_VERY_HIGH
PE2.Mode=Single Bank 1
PE2.Signal=QUADSPI_BK1_IO2
PE3.GPIO_ModeDefaultOutputPP=GPIO_MODE_OUTPUT_PP
PE3.GPIO_PuPd=GPIO_PULLDOWN
PE3.PinState=GPIO_PIN_RESET
PE3.Signal=GPIO_Output
PE4.GPIO_PuPd=GPIO_PULLDOWN
PE4.PinState=GPIO_PIN_RESET
PE4.Signal=GPIO_Output
PE5.GPIO_PuPd=GPIO_PULLDOWN
PE5.Signal=GPIO_Input
PE6.GPIO_PuPd=GPIO_PULLUP
PE6.Signal=GPIO_Input
PE7.Signal=FMC_D4_DA4
PE8.Signal=FMC_D5_DA5
PE9.Signal=FMC_D6_DA6
PF0.Signal=FMC_A0
PF1.Signal=FMC_A1
PF11.Signal=FMC_SDNRAS
PF12.Signal=FMC_A6
PF13.Signal=FMC_A7
PF14.Signal=FMC_A8
PF15.Signal=FMC_A9
PF2.Signal=FMC_A2
PF3.Signal=FMC_A3
PF4.Signal=FMC_A4
PF5.Signal=FMC_A5
PF6.GPIO_PuPd=GPIO_PULLDOWN
PF6.Signal=S_TIM16_CH1
PF7.Mode=IN3-Single-Ended
PF7.Signal=ADC3_INP3
PF8.GPIO_PuPd=GPIO_PULLUP
PF8.Signal=GPIO_Input
PG0.Signal=FMC_A10
PG1.Signal=FMC_A11
PG10.PinAttribute=Free
PG10.Signal=GPIO_Output
PG11.GPIO_Speed=GPIO_SPEED_FREQ_VERY_HIGH
PG11.Mode=TX_Only_Simplex_Unidirect_Master
PG11.PinAttribute=Free
PG11.Signal=SPI1_SCK
PG12.GPIO_PuPd=GPIO_PULLDOWN
PG12.PinAttribute=Free
PG12.Signal=GPIO_Output
PG13.GPIO_PuPd=GPIO_PULLUP
PG13.PinAttribute=Free
PG13.Signal=GPIO_Input
PG15.PinAttribute=Free
PG15.Signal=FMC_SDNCAS
PG2.GPIO_PuPd=GPIO_PULLUP
PG2.Signal=GPIO_Input
PG3.GPIO_PuPd=GPIO_PULLUP
PG3.Signal=GPIO_Input
PG4.Signal=FMC_A14_BA0
PG5.Signal=FMC_A15_BA1
PG6.GPIO_PuPd=GPIO_PULLUP
PG6.Signal=GPIO_Input
PG8.Signal=FMC_SDCLK
PH0-OSC_IN\ (PH0).Mode=HSE-External-Oscillator
PH0-OSC_IN\ (PH0).Signal=RCC_OSC_IN
PH1-OSC_OUT\ (PH1).Mode=HSE-External-Oscillator
PH1-OSC_OUT\ (PH1).Signal=RCC_OSC_OUT
ProjectManager.HeapSize=0x10000
ProjectManager.StackSize=0x1000
ProjectManager.TargetToolchain=MDK-ARM V5.32
QUADSPI.ChipSelectHighTime=QSPI_CS_HIGH_TIME_6_CYCLE
QUADSPI.ClockMode=QSPI_CLOCK_MODE_3
QUADSPI.ClockPrescaler=1
QUADSPI.FifoThreshold=24
QUADSPI.FlashSize=24
QUADSPI.SampleShifting=QSPI_SAMPLE_SHIFTING_HALFCYCLE
RCC.ADCCLockSelection=RCC_ADCCLKSOURCE_CLKP
RCC.ADCFreq_Value=12000000
RCC.APB1Freq_Value=120000000
RCC.APB2Freq_Value=120000000
RCC.APB3Freq_Value=120000000
RCC.APB4Freq_Value=120000000
RCC.CKPERSourceSelection=RCC_CLKPSOURCE_HSE
RCC.CortexFreq_Value=480000000
RCC.D1PPRE=RCC_APB3_DIV2
RCC.D2PPRE1=RCC_APB1_DIV2
RCC.D2PPRE2=RCC_APB2_DIV2
RCC.D3PPRE=RCC_APB4_DIV2
RCC.DIVM1=1
RCC.DIVM2=1
RCC.DIVM3=1
RCC.DIVN1=80
RCC.DIVN2=20
RCC.DIVN3=4
RCC.DIVP3=8
RCC.DIVQ1=5
RCC.DIVR2=1
RCC.DIVR3=1
RCC.EnbaleCSS=true
RCC.HCLKFreq_Value=240000000
RCC.HPRE=RCC_HCLK_DIV2
RCC.HSE_VALUE=12000000
RCC.PLL2FRACN=4096
RCC.PLL2_VCI_Range-AdvancedSettings=RCC_PLL2VCIRANGE_0
RCC.PLL3FRACN=0
RCC.PLL3_VCO_SEL-AdvancedSettings=RCC_PLL3VCOMEDIUM
RCC.PLLFRACN=0
RCC.PLLSourceVirtual=RCC_PLLSOURCE_HSE
RCC.QSPICLockSelection=RCC_QSPICLKSOURCE_PLL
RCC.RTCClockSelection=RCC_RTCCLKSOURCE_LSE
RCC.SDMMC1CLockSelection=RCC_SDMMCCLKSOURCE_PLL2
RCC.SYSCLKFreq_VALUE=480000000
RCC.SYSCLKSource=RCC_SYSCLKSOURCE_PLLCLK
RCC.Tim2Mul=1
RCC.USBCLockSelection=RCC_USBCLKSOURCE_HSI48
RCC.USBFreq_Value=48000000
SDMMC1.ClockDiv=0
SDMMC1.ClockEdge=SDMMC_CLOCK_EDGE_RISING
SDMMC1.ClockPowerSave=SDMMC_CLOCK_POWER_SAVE_ENABLE
SDMMC1.HardwareFlowControl=SDMMC_HARDWARE_FLOW_CONTROL_ENABLE
SDMMC1.TransceiverPresent=SDMMC_TRANSCEIVER_NOT_PRESENT
SH.ADCx_INP11.0=ADC1_INP11,IN11-Single-Ended
SH.ADCx_INP15.0=ADC1_INP15,IN15-Single-Ended
SH.ADCx_INP19.0=ADC1_INP19,IN19-Single-Ended
SH.ADCx_INP4.0=ADC2_INP4
SH.ADCx_INP4.1=ADC1_INP4,IN4-Single-Ended
SH.ADCx_INP8.0=ADC1_INP8,IN8-Single-Ended
SH.ADCx_INP9.0=ADC1_INP9,IN9-Single-Ended
SH.COMP_DAC11_group.0=DAC1_OUT1,DAC_OUT1
SH.FMC_A0.0=FMC_A0,12b-sda1
SH.FMC_A1.0=FMC_A1,12b-sda1
SH.FMC_A10.0=FMC_A10,12b-sda1
SH.FMC_A11.0=FMC_A11,12b-sda1
SH.FMC_A14_BA0.0=FMC_BA0,FourSdramBanks1
SH.FMC_A15_BA1.0=FMC_BA1,FourSdramBanks1
SH.FMC_A2.0=FMC_A2,12b-sda1
SH.FMC_A3.0=FMC_A3,12b-sda1
SH.FMC_A4.0=FMC_A4,12b-sda1
SH.FMC_A5.0=FMC_A5,12b-sda1
SH.FMC_A6.0=FMC_A6,12b-sda1
SH.FMC_A7.0=FMC_A7,12b-sda1
SH.FMC_A8.0=FMC_A8,12b-sda1
SH.FMC_A9.0=FMC_A9,12b-sda1
SH.FMC_D0_DA0.0=FMC_D0,sd-16b-d1
SH.FMC_D10_DA10.0=FMC_D10,sd-16b-d1
SH.FMC_D11_DA11.0=FMC_D11,sd-16b-d1
SH.FMC_D12_DA12.0=FMC_D12,sd-16b-d1
SH.FMC_D13_DA13.0=FMC_D13,sd-16b-d1
SH.FMC_D14_DA14.0=FMC_D14,sd-16b-d1
SH.FMC_D15_DA15.0=FMC_D15,sd-16b-d1
SH.FMC_D1_DA1.0=FMC_D1,sd-16b-d1
SH.FMC_D2_DA2.0=FMC_D2,sd-16b-d1
SH.FMC_D3_DA3.0=FMC_D3,sd-16b-d1
SH.FMC_D4_DA4.0=FMC_D4,sd-16b-d1
SH.FMC_D5_DA5.0=FMC_D5,sd-16b-d1
SH.FMC_D6_DA6.0=FMC_D6,sd-16b-d1
SH.FMC_D7_DA7.0=FMC_D7,sd-16b-d1
SH.FMC_D8_DA8.0=FMC_D8,sd-16b-d1
SH.FMC_D9_DA9.0=FMC_D9,sd-16b-d1
SH.FMC_NBL0.0=FMC_NBL0,Sd2ByteEnable1
SH.FMC_NBL1.0=FMC_NBL1,Sd2ByteEnable1
SH.FMC_SDCLK.0=FMC_SDCLK,12b-sda1
SH.FMC_SDNCAS.0=FMC_SDNCAS,12b-sda1
SH.FMC_SDNRAS.0=FMC_SDNRAS,12b-sda1
SH.FMC_SDNWE.0=FMC_SDNWE,12b-sda1
SH.S_TIM16_CH1.0=TIM16_CH1,PWM Generation1 CH1
SH.S_TIM1_CH2.0=TIM1_CH2,PWM Generation2 CH2
SH.S_TIM2_CH1_ETR.0=TIM2_CH1,PWM Generation1 CH1
SH.S_TIM2_CH2.0=TIM2_CH2,PWM Generation2 CH2
SH.S_TIM3_CH1.0=TIM3_CH1,Encoder_Interface
SH.S_TIM3_CH2.0=TIM3_CH2,Encoder_Interface
SPI1.BaudRatePrescaler=SPI_BAUDRATEPRESCALER_2
SPI1.CalculateBaudRate=96.0 MBits/s
SPI1.DataSize=SPI_DATASIZE_8BIT
SPI1.Direction=SPI_DIRECTION_2LINES_TXONLY
SPI1.FifoThreshold=SPI_FIFO_THRESHOLD_01DATA
SPI1.FirstBit=SPI_FIRSTBIT_MSB
SPI1.MasterInterDataIdleness=SPI_MASTER_INTERDATA_IDLENESS_15CYCLE
SPI1.MasterKeepIOState=SPI_MASTER_KEEP_IO_STATE_DISABLE
SPI1.MasterSSIdleness=SPI_MASTER_SS_IDLENESS_15CYCLE
SPI1.Mode=SPI_MODE_MASTER
SPI1.NSSPMode=SPI_NSS_PULSE_DISABLE
SPI1.VirtualType=VM_MASTER
TIM1.AutoReloadPreload=TIM_AUTORELOAD_PRELOAD_DISABLE
TIM1.Channel-PWM\ Generation2\ CH2=TIM_CHANNEL_2
TIM1.OC2Preload_PWM=ENABLE
TIM1.OCFastMode_PWM-PWM\ Generation2\ CH2=TIM_OCFAST_DISABLE
TIM1.OCIdleState_2=TIM_OCIDLESTATE_RESET
TIM1.OCMode_PWM-PWM\ Generation2\ CH2=TIM_OCMODE_PWM1
TIM1.OCPolarity_2=TIM_OCPOLARITY_LOW
TIM1.Period=500
TIM1.Prescaler=10-1
TIM1.RepetitionCounter=0
TIM15.AutoReloadPreload=TIM_AUTORELOAD_PRELOAD_ENABLE
TIM15.Period=30000-1
TIM15.Prescaler=1-1
TIM15.TIM_MasterOutputTrigger=TIM_TRGO_UPDATE
TIM16.Channel=TIM_CHANNEL_1
TIM16.Period=\ (295 + 595) * 240 / 1000 -1
TIM16.Prescaler=0
TIM2.AutoReloadPreload=TIM_AUTORELOAD_PRELOAD_ENABLE
TIM2.Channel-PWM\ Generation1\ CH1=TIM_CHANNEL_1
TIM2.Channel-PWM\ Generation2\ CH2=TIM_CHANNEL_2
TIM2.OCFastMode_PWM-PWM\ Generation1\ CH1=TIM_OCFAST_ENABLE
TIM2.Period=10000-1
TIM2.Prescaler=0
TIM3.EncoderMode=TIM_ENCODERMODE_TI12
TIM3.IC1Filter=15
TIM3.IC1Polarity=TIM_ICPOLARITY_RISING
TIM3.IC1Prescaler=TIM_ICPSC_DIV2
TIM3.IC2Filter=15
TIM3.IC2Polarity=TIM_ICPOLARITY_RISING
TIM3.IC2Prescaler=TIM_ICPSC_DIV2
TIM3.Prescaler=0
TIM5.AutoReloadPreload=TIM_AUTORELOAD_PRELOAD_ENABLE
TIM5.Prescaler=240-1
UART4.BaudRate=1500000
UART4.FIFOMode=FIFOMODE_DISABLE
UART4.RXFIFOThreshold=RXFIFO_THRESHOLD_1EIGHTHFULL
UART4.TXFIFOThreshold=TXFIFO_THRESHOLD_1EIGHTHFULL
UART5.BaudRate=1000000
UART5.FIFOMode=FIFOMODE_DISABLE
UART5.Mode=MODE_TX
USART1.BaudRate=115200
USART1.FIFOMode=FIFOMODE_DISABLE
USART1.VirtualMode-Asynchronous=VM_ASYNC
USART1.VirtualMode-Half_duplex(single_wire_mode)=VM_ASYNC
USART2.BaudRate=921600
USART2.FIFOMode=FIFOMODE_ENABLE
USART2.VirtualMode-Asynchronous=VM_ASYNC
USART6.BaudRate=115200
USART6.VirtualMode-Asynchronous=VM_ASYNC
USB_DEVICE.CLASS_NAME_FS=CDC
USB_DEVICE.VirtualMode-CDC_FS=Cdc
USB_DEVICE.VirtualModeFS=Cdc_FS
USB_OTG_FS.VirtualMode=Device_Only
VP_FATFS_VS_SDIO.Mode=SDIO
VP_FREERTOS_VS_CMSIS_V2.Mode=CMSIS_V2
VP_IWDG1_VS_IWDG.Mode=IWDG_Activate
VP_MEMORYMAP_VS_MEMORYMAP.Mode=CurAppReg
VP_RTC_VS_RTC_Activate.Mode=RTC_Enabled
VP_SYS_VS_tim12.Mode=TIM12
VP_TIM15_VS_ClockSourceINT.Mode=Internal
VP_TIM16_VS_ClockSourceINT.Mode=Enable_Timer
VP_TIM5_VS_ClockSourceINT.Mode=Internal
VP_USB_DEVICE_VS_USB_DEVICE_CDC_FS.Mode=CDC_FS
board=custom

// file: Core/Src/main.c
/* USER CODE BEGIN Header */
/**
 ******************************************************************************
 * @file           : main.c
 * @brief          : Main program body
 ******************************************************************************
 * @attention
 *
 * Copyright (c) 2024 STMicroelectronics.
 * All rights reserved.
 *
 * This software is licensed under terms that can be found in the LICENSE file
 * in the root directory of this software component.
 * If no LICENSE file comes with this software, it is provided AS-IS.
 *
 ******************************************************************************
 */
/* USER CODE END Header */
#include "main.h"
#include "cmsis_os.h"
#include "adc.h"
#include "dac.h"
#include "dma.h"
#include "fatfs.h"
#include "i2c.h"
#include "iwdg.h"
#include "memorymap.h"
#include "rtc.h"
#include "sdmmc.h"
#include "spi.h"
#include "tim.h"
#include "usart.h"
#include "usb_device.h"
#include "gpio.h"
#include "fmc.h"

void SystemClock_Config(void);
void PeriphCommonClock_Config(void);
static void MPU_Config(void);
void MX_FREERTOS_Init(void);

int main(void)
{

  /* MPU Configuration--------------------------------------------------------*/
  MPU_Config();

  /* Enable the CPU Cache */

  /* Enable I-Cache---------------------------------------------------------*/
  SCB_EnableICache();

  /* Enable D-Cache---------------------------------------------------------*/
  SCB_EnableDCache();

  /* MCU Configuration--------------------------------------------------------*/

  /* Reset of all peripherals, Initializes the Flash interface and the Systick. */
  HAL_Init();

  /* Configure the system clock */
  SystemClock_Config();

  /* Configure the peripherals common clocks */
  PeriphCommonClock_Config();

  /* USER CODE BEGIN SysInit */
    void msp_first_init(void);
    msp_first_init();

  /* USER CODE END SysInit */

  /* Initialize all configured peripherals */
  MX_GPIO_Init();
  MX_DMA_Init();
  MX_TIM5_Init();
  MX_DAC1_Init();
  MX_TIM15_Init();
  MX_I2C1_Init();
  MX_I2C2_Init();
  MX_SDMMC1_SD_Init();
  MX_UART4_Init();
  MX_FATFS_Init();
  MX_TIM2_Init();
  MX_TIM1_Init();
  MX_SPI1_Init();
  MX_FMC_Init();
  MX_ADC1_Init();
  MX_USART2_UART_Init();
  MX_TIM16_Init();
  MX_TIM3_Init();
  MX_ADC3_Init();
  MX_UART5_Init();
  MX_RTC_Init();
  MX_USART6_UART_Init();
  MX_USART1_UART_Init();
  MX_IWDG1_Init();
  /* USER CODE BEGIN 2 */
    void msp_init(void);
    msp_init();

  /* USER CODE END 2 */

  /* Init scheduler */
  osKernelInitialize();

  /* Call init function for freertos objects (in cmsis_os2.c) */
  MX_FREERTOS_Init();

  /* Start scheduler */
  osKernelStart();

  /* We should never get here as control is now taken by the scheduler */

  /* Infinite loop */
    while (1)
    {

    }
}

void SystemClock_Config(void)
{
  RCC_OscInitTypeDef RCC_OscInitStruct = {0};
  RCC_ClkInitTypeDef RCC_ClkInitStruct = {0};

  /** Supply configuration update enable
  */
  HAL_PWREx_ConfigSupply(PWR_LDO_SUPPLY);

  /** Configure the main internal regulator output voltage
  */
  __HAL_PWR_VOLTAGESCALING_CONFIG(PWR_REGULATOR_VOLTAGE_SCALE1);

  while(!__HAL_PWR_GET_FLAG(PWR_FLAG_VOSRDY)) {}

  __HAL_RCC_SYSCFG_CLK_ENABLE();
  __HAL_PWR_VOLTAGESCALING_CONFIG(PWR_REGULATOR_VOLTAGE_SCALE0);

  while(!__HAL_PWR_GET_FLAG(PWR_FLAG_VOSRDY)) {}

  /** Configure LSE Drive Capability
  */
  HAL_PWR_EnableBkUpAccess();
  __HAL_RCC_LSEDRIVE_CONFIG(RCC_LSEDRIVE_LOW);

  /** Initializes the RCC Oscillators according to the specified parameters
  * in the RCC_OscInitTypeDef structure.
  */
  RCC_OscInitStruct.OscillatorType = RCC_OSCILLATORTYPE_HSI48|RCC_OSCILLATORTYPE_LSI
                              |RCC_OSCILLATORTYPE_HSE|RCC_OSCILLATORTYPE_LSE;
  RCC_OscInitStruct.HSEState = RCC_HSE_ON;
  RCC_OscInitStruct.LSEState = RCC_LSE_ON;
  RCC_OscInitStruct.LSIState = RCC_LSI_ON;
  RCC_OscInitStruct.HSI48State = RCC_HSI48_ON;
  RCC_OscInitStruct.PLL.PLLState = RCC_PLL_ON;
  RCC_OscInitStruct.PLL.PLLSource = RCC_PLLSOURCE_HSE;
  RCC_OscInitStruct.PLL.PLLM = 1;
  RCC_OscInitStruct.PLL.PLLN = 80;
  RCC_OscInitStruct.PLL.PLLP = 2;
  RCC_OscInitStruct.PLL.PLLQ = 5;
  RCC_OscInitStruct.PLL.PLLR = 2;
  RCC_OscInitStruct.PLL.PLLRGE = RCC_PLL1VCIRANGE_3;
  RCC_OscInitStruct.PLL.PLLVCOSEL = RCC_PLL1VCOWIDE;
  RCC_OscInitStruct.PLL.PLLFRACN = 0;
  if (HAL_RCC_OscConfig(&RCC_OscInitStruct) != HAL_OK)
  {
    Error_Handler();
  }

  /** Initializes the CPU, AHB and APB buses clocks
  */
  RCC_ClkInitStruct.ClockType = RCC_CLOCKTYPE_HCLK|RCC_CLOCKTYPE_SYSCLK
                              |RCC_CLOCKTYPE_PCLK1|RCC_CLOCKTYPE_PCLK2
                              |RCC_CLOCKTYPE_D3PCLK1|RCC_CLOCKTYPE_D1PCLK1;
  RCC_ClkInitStruct.SYSCLKSource = RCC_SYSCLKSOURCE_PLLCLK;
  RCC_ClkInitStruct.SYSCLKDivider = RCC_SYSCLK_DIV1;
  RCC_ClkInitStruct.AHBCLKDivider = RCC_HCLK_DIV2;
  RCC_ClkInitStruct.APB3CLKDivider = RCC_APB3_DIV2;
  RCC_ClkInitStruct.APB1CLKDivider = RCC_APB1_DIV2;
  RCC_ClkInitStruct.APB2CLKDivider = RCC_APB2_DIV2;
  RCC_ClkInitStruct.APB4CLKDivider = RCC_APB4_DIV2;

  if (HAL_RCC_ClockConfig(&RCC_ClkInitStruct, FLASH_LATENCY_4) != HAL_OK)
  {
    Error_Handler();
  }

  /** Enables the Clock Security System
  */
  HAL_RCC_EnableCSS();
}

void PeriphCommonClock_Config(void)
{
  RCC_PeriphCLKInitTypeDef PeriphClkInitStruct = {0};

  /** Initializes the peripherals clock
  */
  PeriphClkInitStruct.PeriphClockSelection = RCC_PERIPHCLK_CKPER;
  PeriphClkInitStruct.CkperClockSelection = RCC_CLKPSOURCE_HSE;
  if (HAL_RCCEx_PeriphCLKConfig(&PeriphClkInitStruct) != HAL_OK)
  {
    Error_Handler();
  }
}

 /* MPU Configuration */

void MPU_Config(void)
{
  MPU_Region_InitTypeDef MPU_InitStruct = {0};

  /* Disables the MPU */
  HAL_MPU_Disable();

  /** Initializes and configures the Region and the memory to be protected
  */
  MPU_InitStruct.Enable = MPU_REGION_ENABLE;
  MPU_InitStruct.Number = MPU_REGION_NUMBER0;
  MPU_InitStruct.BaseAddress = 0x24000000;
  MPU_InitStruct.Size = MPU_REGION_SIZE_512KB;
  MPU_InitStruct.SubRegionDisable = 0x0;
  MPU_InitStruct.TypeExtField = MPU_TEX_LEVEL0;
  MPU_InitStruct.AccessPermission = MPU_REGION_FULL_ACCESS;
  MPU_InitStruct.DisableExec = MPU_INSTRUCTION_ACCESS_ENABLE;
  MPU_InitStruct.IsShareable = MPU_ACCESS_NOT_SHAREABLE;
  MPU_InitStruct.IsCacheable = MPU_ACCESS_CACHEABLE;
  MPU_InitStruct.IsBufferable = MPU_ACCESS_NOT_BUFFERABLE;

  HAL_MPU_ConfigRegion(&MPU_InitStruct);

  /** Initializes and configures the Region and the memory to be protected
  */
  MPU_InitStruct.Number = MPU_REGION_NUMBER1;
  MPU_InitStruct.BaseAddress = 0x30000000;
  MPU_InitStruct.Size = MPU_REGION_SIZE_128KB;

  HAL_MPU_ConfigRegion(&MPU_InitStruct);

  /** Initializes and configures the Region and the memory to be protected
  */
  MPU_InitStruct.Number = MPU_REGION_NUMBER2;
  MPU_InitStruct.BaseAddress = 0x30020000;

  HAL_MPU_ConfigRegion(&MPU_InitStruct);
  /* Enables the MPU */
  HAL_MPU_Enable(MPU_HFNMI_PRIVDEF);

}

void HAL_TIM_PeriodElapsedCallback(TIM_HandleTypeDef *htim)
{
  /* USER CODE BEGIN Callback 0 */
    if (htim->Instance != TIM12)
    {
        void TIM_PeriodElapsedCallback(TIM_HandleTypeDef * htim);
        TIM_PeriodElapsedCallback(htim);
    }
  /* USER CODE END Callback 0 */
  if (htim->Instance == TIM12) {
    HAL_IncTick();
  }
}

void Error_Handler(void)
{
    __disable_irq();
    while (1)
    {
    }
}

#ifdef  USE_FULL_ASSERT
/**
  * @brief  Reports the name of the source file and the source line number
  *         where the assert_param error has occurred.
  * @param  file: pointer to the source file name
  * @param  line: assert_param error line source number
  * @retval None
  */
void assert_failed(uint8_t *file, uint32_t line)
{
  /* USER CODE BEGIN 6 */
    void error_from(char *file, uint32_t line);
    error_from((char *)file, line);
    /* User can add his own implementation to report the file name and line number,
       ex: printf("Wrong parameters value: file %s on line %d\r\n", file, line) */
  /* USER CODE END 6 */
}
#endif /* USE_FULL_ASSERT */

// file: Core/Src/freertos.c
/* USER CODE BEGIN Header */
/**
  ******************************************************************************
  * File Name          : freertos.c
  * Description        : Code for freertos applications
  ******************************************************************************
  * @attention
  *
  * Copyright (c) 2024 STMicroelectronics.
  * All rights reserved.
  *
  * This software is licensed under terms that can be found in the LICENSE file
  * in the root directory of this software component.
  * If no LICENSE file comes with this software, it is provided AS-IS.
  *
  ******************************************************************************
  */
/* USER CODE END Header */

#include "FreeRTOS.h"
#include "task.h"
#include "main.h"
#include "cmsis_os.h"

typedef StaticTask_t osStaticThreadDef_t;

/* Definitions for defaultTask */
osThreadId_t defaultTaskHandle;
uint32_t defaultTaskBuffer[ 1024 ];
osStaticThreadDef_t defaultTaskControlBlock;
const osThreadAttr_t defaultTask_attributes = {
  .name = "defaultTask",
  .cb_mem = &defaultTaskControlBlock,
  .cb_size = sizeof(defaultTaskControlBlock),
  .stack_mem = &defaultTaskBuffer[0],
  .stack_size = sizeof(defaultTaskBuffer),
  .priority = (osPriority_t) osPriorityLow,
};

void StartDefaultTask(void *argument);

extern void MX_USB_DEVICE_Init(void);
void MX_FREERTOS_Init(void); /* (MISRA C 2004 rule 8.1) */

/* Hook prototypes */
void configureTimerForRunTimeStats(void);
unsigned long getRunTimeCounterValue(void);
void vApplicationStackOverflowHook(xTaskHandle xTask, signed char *pcTaskName);
void vApplicationMallocFailedHook(void);

/* USER CODE BEGIN 1 */
/* Functions needed when configGENERATE_RUN_TIME_STATS is on */
__weak void configureTimerForRunTimeStats(void)
{

}

__weak unsigned long getRunTimeCounterValue(void)
{
return 0;
}
/* USER CODE END 1 */

/* USER CODE BEGIN 4 */
void vApplicationStackOverflowHook(xTaskHandle xTask, signed char *pcTaskName)
{
   /* Run time stack overflow checking is performed if
   configCHECK_FOR_STACK_OVERFLOW is defined to 1 or 2. This hook function is
   called if a stack overflow is detected. */
}
/* USER CODE END 4 */

/* USER CODE BEGIN 5 */
void vApplicationMallocFailedHook(void)
{
   /* vApplicationMallocFailedHook() will only be called if
   configUSE_MALLOC_FAILED_HOOK is set to 1 in FreeRTOSConfig.h. It is a hook
   function that will get called if a call to pvPortMalloc() fails.
   pvPortMalloc() is called internally by the kernel whenever a task, queue,
   timer or semaphore is created. It is also called by various parts of the
   demo application. If heap_1.c or heap_2.c are used, then the size of the
   heap available to pvPortMalloc() is defined by configTOTAL_HEAP_SIZE in
   FreeRTOSConfig.h, and the xPortGetFreeHeapSize() API function can be used
   to query the size of free heap space that remains (although it does not
   provide information on how the remaining heap might be fragmented). */
}
/* USER CODE END 5 */

void MX_FREERTOS_Init(void) {

  /* Create the thread(s) */
  /* creation of defaultTask */
  defaultTaskHandle = osThreadNew(StartDefaultTask, NULL, &defaultTask_attributes);

}

void StartDefaultTask(void *argument)
{
  /* init code for USB_DEVICE */
  MX_USB_DEVICE_Init();
  for(;;)
  {
    osDelay(1);
  }
}
